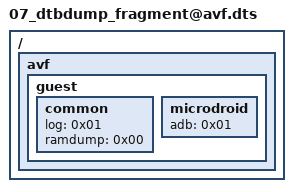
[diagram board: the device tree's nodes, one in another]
/dts-v1/;

/ {

	fragment@avf {
		target-path = "/";

		__overlay__ {

			avf {

				guest {

					common {
						log = <0x01>;
						ramdump = <0x00>;
					};

					microdroid {
						adb = <0x01>;
					};
				};
			};
		};
	};

	__fixups__ {
	};
};
